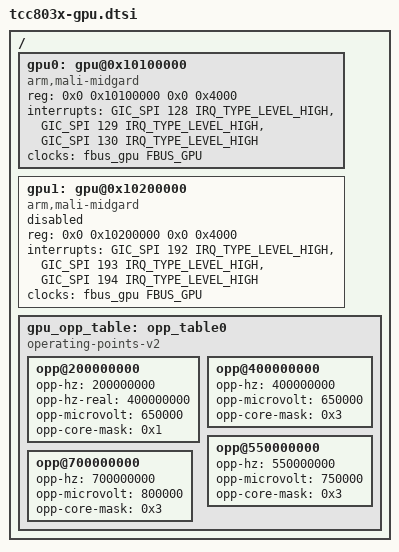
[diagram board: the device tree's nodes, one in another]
// SPDX-License-Identifier: (GPL-2.0-or-later OR MIT)
/*
 * Copyright (C) 2023 Telechips Inc.
 */



/ {
	gpu0:gpu@0x10100000 {
		compatible = "arm,mali-midgard";
		reg = <0x0 0x10100000 0x0 0x4000>;
		interrupts = <GIC_SPI 128 IRQ_TYPE_LEVEL_HIGH>,
			     <GIC_SPI 129 IRQ_TYPE_LEVEL_HIGH>,
			     <GIC_SPI 130 IRQ_TYPE_LEVEL_HIGH>;
		interrupt-names = "JOB", "MMU", "GPU";
		clocks = <&fbus_gpu FBUS_GPU>;
		clock-names = "mali_clk";
		/*operating-points-v2 = <&gpu_opp_table>;*/
	};

	gpu1: gpu@0x10200000 {
		compatible = "arm,mali-midgard";
		status = "disabled";
		reg = <0x0 0x10200000 0x0 0x4000>;
		interrupts = <GIC_SPI 192 IRQ_TYPE_LEVEL_HIGH>,
			     <GIC_SPI 193 IRQ_TYPE_LEVEL_HIGH>,
			     <GIC_SPI 194 IRQ_TYPE_LEVEL_HIGH>;
		interrupt-names = "JOB", "MMU", "GPU";
		clocks = <&fbus_gpu FBUS_GPU>;
		clock-names = "mali_clk";
	};

	gpu_opp_table: opp_table0 {
		compatible = "operating-points-v2", "operating-points-v2-mali";

		opp@200000000 {
			opp-hz = /bits/ 64 <200000000>;
			opp-hz-real = /bits/ 64 <400000000>;
			opp-microvolt = <650000>;
			opp-core-mask = /bits/ 64 <0x1>;
		};
		opp@400000000 {
			opp-hz = /bits/ 64 <400000000>;
			opp-microvolt = <650000>;
			opp-core-mask = /bits/ 64 <0x3>;
		};
		opp@550000000 {
			opp-hz = /bits/ 64 <550000000>;
			opp-microvolt = <750000>;
			opp-core-mask = /bits/ 64 <0x3>;
		};
		opp@700000000 {
			opp-hz = /bits/ 64 <700000000>;
			opp-microvolt = <800000>;
			opp-core-mask = /bits/ 64 <0x3>;
		};
	};
};
